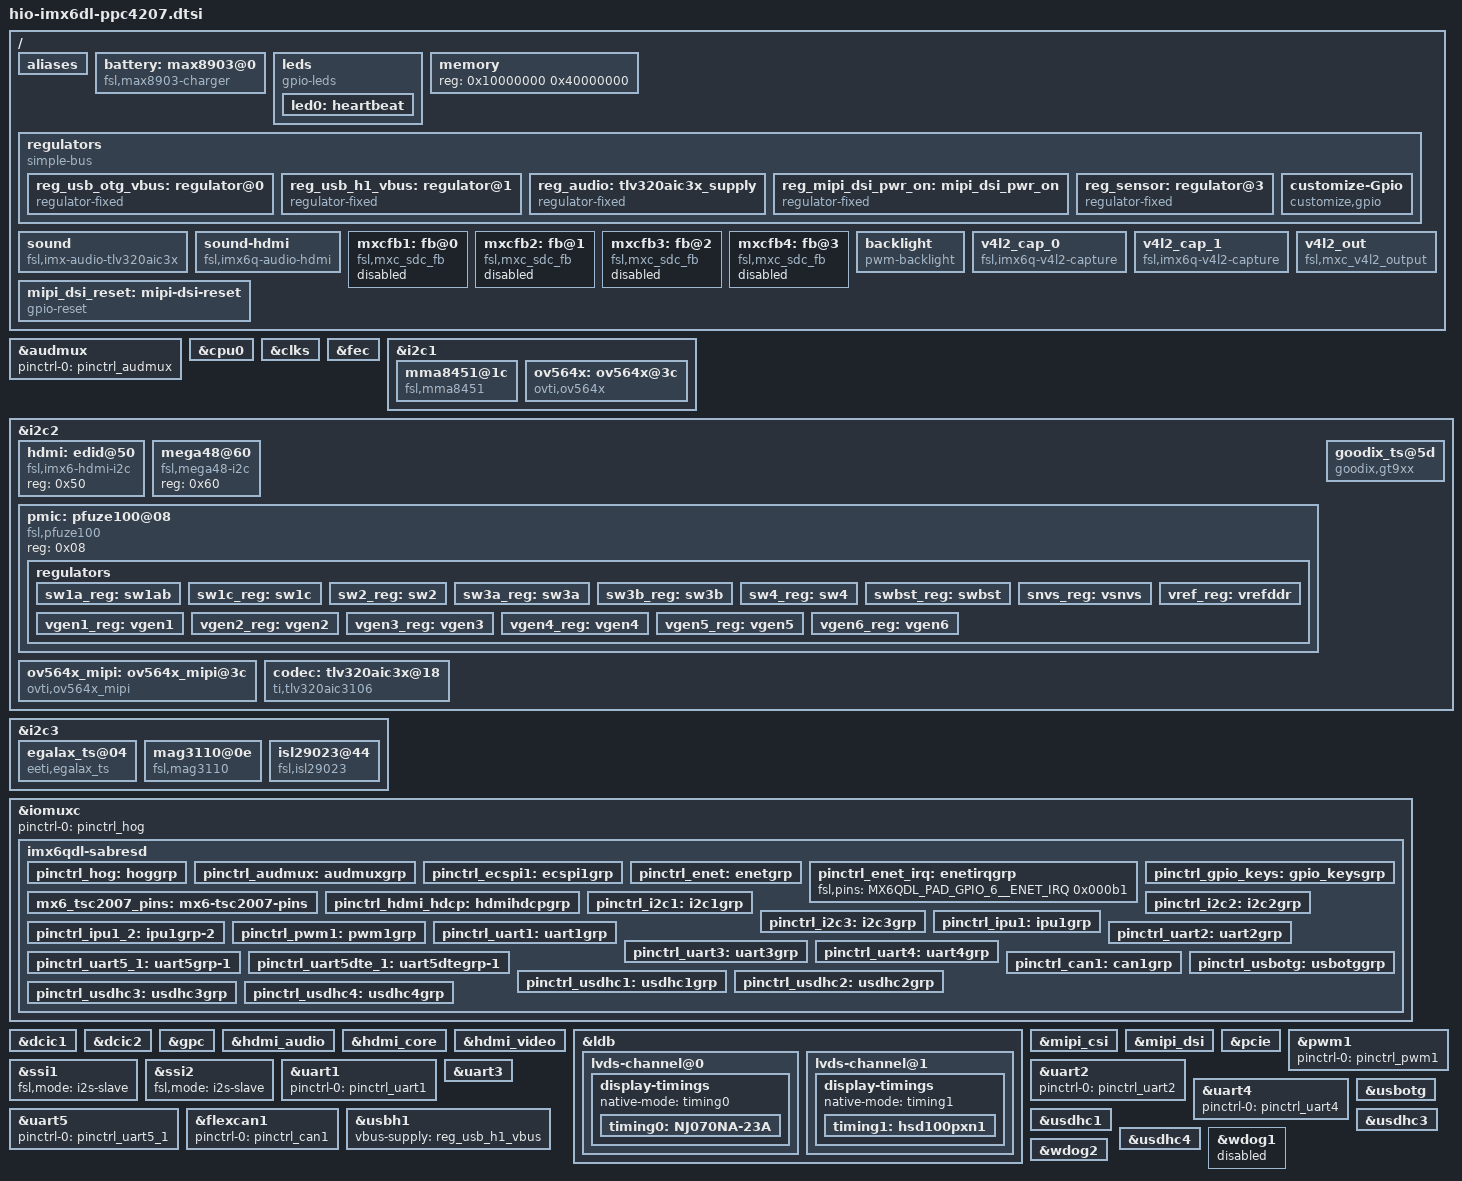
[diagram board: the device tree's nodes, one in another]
/*
 * Copyright 2012 Freescale Semiconductor, Inc.
 * Copyright 2011 Linaro Ltd.
 *
 * The code contained herein is licensed under the GNU General Public
 * License. You may obtain a copy of the GNU General Public License
 * Version 2 or later at the following locations:
 *
 * http://www.opensource.org/licenses/gpl-license.html
 * http://www.gnu.org/copyleft/gpl.html
 */

#include <dt-bindings/input/input.h>

/ {
	aliases {
		mxcfb0 = &mxcfb1;
		mxcfb1 = &mxcfb2;
		mxcfb2 = &mxcfb3;
		mxcfb3 = &mxcfb4;
	};

	battery: max8903@0 {
		compatible = "fsl,max8903-charger";
		pinctrl-names = "default";
		dok_input = <&gpio2 24 1>;
		uok_input = <&gpio1 27 1>;
		chg_input = <&gpio3 23 1>;
		flt_input = <&gpio5 2 1>;
		fsl,dcm_always_high;
		fsl,dc_valid;
		fsl,usb_valid;
		status = "okay";
	};

	#if 0
	hannstar_cabc {
		compatible = "hannstar,cabc";

		lvds0 {
			gpios = <&gpio6 15 GPIO_ACTIVE_HIGH>;
		};

		lvds1 {
			gpios = <&gpio6 16 GPIO_ACTIVE_HIGH>;
		};
	};
	#endif
	
	leds {
		compatible = "gpio-leds";

		led0: heartbeat {
             label = "heartbeat";
             gpios = <&gpio5 18 GPIO_ACTIVE_HIGH>;
             default-state = "off";
             linux,default-trigger = "heartbeat";
         };
	};

	memory: memory {
		reg = <0x10000000 0x40000000>;
	};

	regulators {
		compatible = "simple-bus";
		#address-cells = <1>;
		#size-cells = <0>;

		reg_usb_otg_vbus: regulator@0 {
			compatible = "regulator-fixed";
			reg = <0>;
			regulator-name = "usb_otg_vbus";
			regulator-min-microvolt = <5000000>;
			regulator-max-microvolt = <5000000>;
			gpio = <&gpio3 22 0>;
			enable-active-high;
			regulator-always-on;
		};

		reg_usb_h1_vbus: regulator@1 {
			compatible = "regulator-fixed";
			reg = <1>;
			regulator-name = "usb_h1_vbus";
			regulator-min-microvolt = <5000000>;
			regulator-max-microvolt = <5000000>;
			//gpio = <&gpio1 29 0>;
			enable-active-high;
			regulator-always-on;
		};

		reg_audio: tlv320aic3x_supply {
			compatible = "regulator-fixed";
			regulator-name = "tlv320aic3x-supply";
			enable-active-high;
		};
		
		#if 0
		reg_audio: regulator@2 {
			compatible = "regulator-fixed";
			reg = <2>;
			regulator-name = "wm8962-supply";
			//gpio = <&gpio4 10 0>;
			enable-active-high;
		};
		#endif
		
		reg_mipi_dsi_pwr_on: mipi_dsi_pwr_on {
			compatible = "regulator-fixed";
			regulator-name = "mipi_dsi_pwr_on";
			//gpio = <&gpio6 14 0>;
			enable-active-high;
		};

		reg_sensor: regulator@3 {
			compatible = "regulator-fixed";
			reg = <3>;
			regulator-name = "sensor-supply";
			regulator-min-microvolt = <3300000>;
			regulator-max-microvolt = <3300000>;
			gpio = <&gpio2 31 0>;
			startup-delay-us = <500>;
			enable-active-high;
		};
		
		//emb2230_gpio
		customize-Gpio {
			compatible = "customize,gpio";
			status = "okay";

			//lcd
			//LCD3P3V_Npwren = <&gpio4 11 0>;
			LCD_BL_EN = <&gpio4 17 0>;
			VDDLCD_PWREN = <&gpio4 28 0>;
			
			//tp
			TP_PWR_EN = <&gpio4 10 0>;
			
			//usb hub
			HUB_reset = <&gpio3 20 0>;
			
			//aud_mute
			AUD_MUTE = <&gpio5 00 0>;
			
			//emb2230 wl_pwren,wl_host_wake,vdd_len
			WL_PWREN = <&gpio6 15 0>;
			WL_HOST_WAKE = <&gpio6 14 0>;
			BT_PWREN = <&gpio6 10 0>;
			BT_HOST_WAKE = <&gpio6 8 0>;
			BT_RESET = <&gpio2 22 0>;
			BT_CTS = <&gpio6 05 0>;	//bt_cts--gnd	
			BT_RTS = <&gpio6 04 0>;	//bt_rts--gnd
			
			//ar8035 phy reset
			PHY_RESET = <&gpio1 29 0>;
			
			//can1_stb 
			CAN1_STB = <&gpio4 9 0>;
			
			//wifi-pwr
			WIFI_PWR = <&gpio2 0 0>;			
		};			
	};

	#if 0
	gpio-keys {
		compatible = "gpio-keys";
		pinctrl-names = "default";
		pinctrl-0 = <&pinctrl_gpio_keys>;

		power {
			label = "Power Button";
			gpios = <&gpio3 29 1>;
			gpio-key,wakeup;
			linux,code = <KEY_POWER>;
		};

		volume-up {
			label = "Volume Up";
			gpios = <&gpio1 4 1>;
			gpio-key,wakeup;
			linux,code = <KEY_VOLUMEUP>;
		};
	};
	#endif

	#if 0	
	sound {
		compatible = "fsl,imx-audio-rt5631";
		model = "imx6dl-rt5631";
		ssi-controller = <&ssi1>;
		audio-codec = <&codec>;
		audio-routing =
			"Headphone Jack", "HPOL",
			"Headphone Jack", "HPOR",
			"Ext Spk", "SPOL",
			"Ext Spk", "SPOR";
			//"MICBIAS", "AMIC",
			//"IN3R", "MICBIAS",
			//"DMIC", "MICBIAS",
			//"DMICDAT", "DMIC";
		mux-int-port = <1>;
		mux-ext-port = <4>;
		//hp-det-gpios = <&gpio7 8 1>;
		/*+++wwj begin 20150317@add mic detect*/
		#ifdef CONFIG_MIC_DEC
	              mic-det-gpios = <&gpio7 11 1>;
		#endif
		/*+++wwj end 20150317@add mic detect*/
	};
	#endif
	
	#if 0
	sound {
		compatible = "fsl,imx6q-var-som-tlv320aic3x", "fsl,imx-audio-tlv320aic3x";
		model = "tlv320aic3x-audio";
		ssi-controller = <&ssi1>;
		audio-codec = <&codec>;
		audio-routing =
			/* Headphone connected to HPLOUT, HPROUT */
			"Headphone Jack",       "HPLOUT",
			"Headphone Jack",       "HPROUT",
			/* Line Out connected to LLOUT, RLOUT */
			"Line Out",      	"LLOUT",
			"Line Out",     	"RLOUT",
			/* Mic connected to (MIC3L | MIC3R) */
			"Mic Bias",		"MIC3L",
			"Mic Bias",		"MIC3R",
			"Mic Jack",		"Mic Bias",
			/* Line In connected to (LINE1L | LINE2L), (LINE1R | LINE2R) */
			"Line In",		"LINE1L",
			"Line In",		"LINE2L",
			"Line In",		"LINE1R",
			"Line In",		"LINE2R";
		mux-int-port = <1>;
		mux-ext-port = <4>;
	};
	#endif
	
	//test ok
	sound {
		compatible = "fsl,imx-audio-tlv320aic3x";
		model = "imx6q-phyflex-tlv320aic3007";
		ssi-controller = <&ssi1>;
		audio-codec = <&codec>;
		
		#if 1
		audio-routing =
			"Line Out", "LLOUT",
			"Line Out", "RLOUT",
			"Headphone Jack", "HPLOUT",
			"Headphone Jack", "HPROUT";
		#endif

		#if 0	
                audio-routing = 
                        "Line Out", "LLOUT", 
                        "Line Out", "RLOUT", 
                        "Speaker", "SPOP", 
                        "Speaker", "SPOM", 
                        "Headphone Jack", "HPLOUT", 
                        "Headphone Jack", "HPROUT", 
                        "MIC3L", "Mic Jack", 
                        "MIC3R", "Mic Jack", 
                        "Mic Jack", "Mic Bias", 
                        "LINE1L", "Line In", 
                        "LINE1R", "Line In"; 
		#endif
		
		mux-int-port = <1>;
		mux-ext-port = <4>;
	};
	
	sound-hdmi {
		compatible = "fsl,imx6q-audio-hdmi",
			     "fsl,imx-audio-hdmi";
		model = "imx-audio-hdmi";
		hdmi-controller = <&hdmi_audio>;
	};

	mxcfb1: fb@0 {
		compatible = "fsl,mxc_sdc_fb";
		disp_dev = "ldb";
		interface_pix_fmt = "RGB24";
		mode_str ="NJ070NA-23A";
		default_bpp = <24>;
		int_clk = <0>;
		late_init = <0>;
		status = "disabled";
	};
	
	mxcfb2: fb@1 {
		compatible = "fsl,mxc_sdc_fb";
		disp_dev = "hdmi";
		interface_pix_fmt = "RGB24";
		mode_str ="1920x1080M@60";
		default_bpp = <24>;
		int_clk = <0>;
		late_init = <0>;
		status = "disabled";
	};

	mxcfb3: fb@2 {
		compatible = "fsl,mxc_sdc_fb";
		disp_dev = "lcd";
		interface_pix_fmt = "RGB565";
		mode_str ="CLAA-WVGA";
		default_bpp = <16>;
		int_clk = <0>;
		late_init = <0>;
		status = "disabled";
	};

	mxcfb4: fb@3 {
		compatible = "fsl,mxc_sdc_fb";
		disp_dev = "ldb";
		interface_pix_fmt = "RGB666";
		default_bpp = <16>;
		int_clk = <0>;
		late_init = <0>;
		status = "disabled";
	};

	#if 0
	lcd@0 {
		compatible = "fsl,lcd";
		ipu_id = <0>;
		disp_id = <0>;
		default_ifmt = "RGB565";
		pinctrl-names = "default";
		pinctrl-0 = <&pinctrl_ipu1>;
		status = "okay";
	};
	#endif
	
	backlight {
		compatible = "pwm-backlight";
		pwms = <&pwm1 0 5000000>;
		brightness-levels = <0 4 8 16 32 64 128 255>;
		default-brightness-level = <7>;
		status = "okay";
	};

	v4l2_cap_0 {
		compatible = "fsl,imx6q-v4l2-capture";
		ipu_id = <0>;
		csi_id = <0>;
		mclk_source = <0>;
		status = "okay";
	};

	v4l2_cap_1 {
		compatible = "fsl,imx6q-v4l2-capture";
		ipu_id = <0>;
		csi_id = <1>;
		mclk_source = <0>;
		status = "okay";
	};

	v4l2_out {
		compatible = "fsl,mxc_v4l2_output";
		status = "okay";
	};

	mipi_dsi_reset: mipi-dsi-reset {
		compatible = "gpio-reset";
		reset-gpios = <&gpio6 11 GPIO_ACTIVE_LOW>;
		reset-delay-us = <50>;
		#reset-cells = <0>;
	};
};

&audmux {
	pinctrl-names = "default";
	pinctrl-0 = <&pinctrl_audmux>;
	status = "okay";
};

&cpu0 {
	arm-supply = <&sw1a_reg>;
	soc-supply = <&sw1c_reg>;
};

&clks {
	fsl,ldb-di0-parent = <&clks IMX6QDL_CLK_PLL2_PFD0_352M>;
	fsl,ldb-di1-parent = <&clks IMX6QDL_CLK_PLL2_PFD0_352M>;
};

#if 0
&ecspi1 {
	fsl,spi-num-chipselects = <1>;
	cs-gpios = <&gpio4 9 0>;
	pinctrl-names = "default";
	pinctrl-0 = <&pinctrl_ecspi1>;
	status = "okay";

	flash: m25p80@0 {
		#address-cells = <1>;
		#size-cells = <1>;
		compatible = "st,m25p32";
		spi-max-frequency = <20000000>;
		reg = <0>;
	};
};
#endif

&fec {
	pinctrl-names = "default";
	pinctrl-0 = <&pinctrl_enet>;
	phy-mode = "rgmii";
	phy-reset-gpios = <&gpio1 25 0>;
	fsl,magic-packet;
	status = "okay";
};

&i2c1 {
	clock-frequency = <100000>;
	pinctrl-names = "default";
	pinctrl-0 = <&pinctrl_i2c1>;
	status = "okay";

	mma8451@1c {
		compatible = "fsl,mma8451";
		reg = <0x1c>;
		position = <0>;
		vdd-supply = <&reg_sensor>;
		vddio-supply = <&reg_sensor>;
		interrupt-parent = <&gpio1>;
		interrupts = <18 8>;
		interrupt-route = <1>;
	};
		
	ov564x: ov564x@3c {
		compatible = "ovti,ov564x";
		reg = <0x3c>;
		pinctrl-names = "default";
		pinctrl-0 = <&pinctrl_ipu1_2>;
		clocks = <&clks IMX6QDL_CLK_CKO>;
		clock-names = "csi_mclk";
		DOVDD-supply = <&vgen4_reg>; /* 1.8v */
		AVDD-supply = <&vgen3_reg>;  /* 2.8v, on rev C board is VGEN3,
						on rev B board is VGEN5 */
		DVDD-supply = <&vgen2_reg>;  /* 1.5v*/
		pwn-gpios = <&gpio1 16 1>;   /* active low: SD1_DAT0 */
		rst-gpios = <&gpio1 17 0>;   /* active high: SD1_DAT1 */
		csi_id = <0>;
		mclk = <24000000>;
		mclk_source = <0>;
	};
};

&i2c2 {
	//clock-frequency = <100000>;
	clock-frequency = <50000>;
	pinctrl-names = "default";
	pinctrl-0 = <&pinctrl_i2c2>;
	status = "okay";

	hdmi: edid@50 {
		compatible = "fsl,imx6-hdmi-i2c";
		reg = <0x50>;
	};

	mega48@60 {
		compatible = "fsl,mega48-i2c";
		reg = <0x60>;
	};
	
	pmic: pfuze100@08 {
		compatible = "fsl,pfuze100";
		reg = <0x08>;

		regulators {
			sw1a_reg: sw1ab {
				regulator-min-microvolt = <300000>;
				regulator-max-microvolt = <1875000>;
				regulator-boot-on;
				regulator-always-on;
				regulator-ramp-delay = <6250>;
			};

			sw1c_reg: sw1c {
				regulator-min-microvolt = <300000>;
				regulator-max-microvolt = <1875000>;
				regulator-boot-on;
				regulator-always-on;
				regulator-ramp-delay = <6250>;
			};

			sw2_reg: sw2 {
				regulator-min-microvolt = <800000>;
				regulator-max-microvolt = <3300000>;
				regulator-boot-on;
				regulator-always-on;
				regulator-ramp-delay = <6250>;
			};

			sw3a_reg: sw3a {
				regulator-min-microvolt = <400000>;
				regulator-max-microvolt = <1975000>;
				regulator-boot-on;
				regulator-always-on;
			};

			sw3b_reg: sw3b {
				regulator-min-microvolt = <400000>;
				regulator-max-microvolt = <1975000>;
				regulator-boot-on;
				regulator-always-on;
			};

			sw4_reg: sw4 {
				regulator-min-microvolt = <800000>;
				regulator-max-microvolt = <3300000>;
			};

			swbst_reg: swbst {
				regulator-min-microvolt = <5000000>;
				regulator-max-microvolt = <5150000>;
			};

			snvs_reg: vsnvs {
				regulator-min-microvolt = <1000000>;
				regulator-max-microvolt = <3000000>;
				regulator-boot-on;
				regulator-always-on;
			};

			vref_reg: vrefddr {
				regulator-boot-on;
				regulator-always-on;
			};

			vgen1_reg: vgen1 {
				regulator-min-microvolt = <800000>;
				regulator-max-microvolt = <1550000>;
			};

			vgen2_reg: vgen2 {
				regulator-min-microvolt = <800000>;
				regulator-max-microvolt = <1550000>;
			};

			vgen3_reg: vgen3 {
				regulator-min-microvolt = <1800000>;
				regulator-max-microvolt = <3300000>;
			};

			vgen4_reg: vgen4 {
				regulator-min-microvolt = <1800000>;
				regulator-max-microvolt = <3300000>;
				regulator-always-on;
			};

			vgen5_reg: vgen5 {
				regulator-min-microvolt = <1800000>;
				regulator-max-microvolt = <3300000>;
				regulator-always-on;
			};

			vgen6_reg: vgen6 {
				regulator-min-microvolt = <1800000>;
				regulator-max-microvolt = <3300000>;
				regulator-always-on;
			};
		};
	};

	ov564x_mipi: ov564x_mipi@3c { /* i2c2 driver */
		compatible = "ovti,ov564x_mipi";
		reg = <0x3c>;
		clocks = <&clks 201>;
		clock-names = "csi_mclk";
		DOVDD-supply = <&vgen4_reg>; /* 1.8v */
		AVDD-supply = <&vgen3_reg>;  /* 2.8v, rev C board is VGEN3
						rev B board is VGEN5 */
		DVDD-supply = <&vgen2_reg>;  /* 1.5v*/
		pwn-gpios = <&gpio1 19 1>;   /* active low: SD1_CLK */
		rst-gpios = <&gpio1 20 0>;   /* active high: SD1_DAT2 */
		csi_id = <1>;
		mclk = <24000000>;
		mclk_source = <0>;
	};

	#if 0
	egalax_ts@04 {
		compatible = "eeti,egalax_ts";
		reg = <0x04>;
		interrupt-parent = <&gpio6>;
		interrupts = <8 2>;
		wakeup-gpios = <&gpio6 8 0>;
	};
	#endif
	
	#if 0
	codec: rt5631@1a {
		  compatible = "realtek,rt5631";
		  //compatible = "realtek,alc5631";
		  reg = <0x1a>;
		  clocks = <&clks 201>;
	};
	#endif
	
	
	codec: tlv320aic3x@18 {
		//compatible = "ti,tlv320aic3x";
		compatible = "ti,tlv320aic3106";
		reg = <0x18>;
		ai3x-micbias-vg = <2>;
		
		clocks = <&clks 201>;
		clock-names = "clko_clk";
		IOVDD-supply = <&reg_audio>;
		DVDD-supply = <&reg_audio>;
		AVDD-supply = <&reg_audio>;
		DRVDD-supply = <&reg_audio>;
		gpio-reset = <&gpio5 13 1>;
		gpio-cfg = <
			0x0000 /* 0:Default */
			0x0000 /* 1:Default */
			0x0013 /* 2:FN_DMICCLK */
			0x0000 /* 3:Default */
			0x8014 /* 4:FN_DMICCDAT */
			0x0000 /* 5:Default */
		>;
	};	
	
	//emb2230 tp
	goodix_ts@5d {
		compatible = "goodix,gt9xx";
		reg = <0x5d>;
		interrupt-parent = <&gpio4>;
		interrupts = <27 3>;
		//vdd_ana-supply = <&pm8226_l19>;
		//vcc_i2c-supply = <&pm8226_lvs1>;
		goodix,rst-gpio = <&gpio4 26 0>;
		goodix,irq-gpio = <&gpio4 27 0>;
		goodix,cfg-group0 = [
			42 D0 02 00 05 05 75 01 01 0F 24 
			0F 64 3C 03 05 00 00 00 02 00 00 
			00 16 19 1C 14 8C 0E 0E 24 00 31 
			0D 00 00 00 83 33 1D 00 41 00 00 
			00 00 00 08 0A 00 2B 1C 3C 94 D5 
			03 08 00 00 04 93 1E 00 82 23 00 
			74 29 00 69 2F 00 5F 37 00 5F 20 
			40 60 00 F0 40 30 55 50 27 00 00 
			00 00 00 00 00 00 00 00 00 00 00 
			00 00 00 00 00 00 00 14 19 00 00 
			50 50 02 04 06 08 0A 0C 0E 10 12 
			14 16 18 1A 1C 00 00 00 00 00 00 
			00 00 00 00 00 00 00 00 00 00 1D 
			1E 1F 20 21 22 24 26 28 29 2A 1C 
			18 16 14 13 12 10 0F 0C 0A 08 06 
			04 02 00 00 00 00 00 00 00 00 00 
			00 00 00 00 00 00 00 00 9C 01];
		
		goodix,cfg-group2 = [
			48 D0 02 00 05 05 75 01 01 0F 24 
			0F 64 3C 03 05 00 00 00 02 00 00 
			00 16 19 1C 14 8C 0E 0E 24 00 31 
			0D 00 00 00 83 33 1D 00 41 00 00 
			3C 0A 14 08 0A 00 2B 1C 3C 94 D5 
			03 08 00 00 04 93 1E 00 82 23 00 
			74 29 00 69 2F 00 5F 37 00 5F 20 
			40 60 00 F0 40 30 55 50 27 00 00 
			00 00 00 00 00 00 00 00 00 00 00 
			00 00 00 00 00 00 00 14 19 00 00 
			50 50 02 04 06 08 0A 0C 0E 10 12 
			14 16 18 1A 1C 00 00 00 00 00 00 
			00 00 00 00 00 00 00 00 00 00 1D 
			1E 1F 20 21 22 24 26 28 29 2A 1C 
			18 16 14 13 12 10 0F 0C 0A 08 06 
			04 02 00 00 00 00 00 00 00 00 00 
			00 00 00 00 00 00 00 00 3C 01];
	};			
};

&i2c3 {
	clock-frequency = <100000>;
	pinctrl-names = "default";
	pinctrl-0 = <&pinctrl_i2c3>;
	status = "okay";

	egalax_ts@04 {
		compatible = "eeti,egalax_ts";
		reg = <0x04>;
		interrupt-parent = <&gpio6>;
		interrupts = <7 2>;
		wakeup-gpios = <&gpio6 7 0>;
	};

	mag3110@0e {
		compatible = "fsl,mag3110";
		reg = <0x0e>;
		position = <2>;
		vdd-supply = <&reg_sensor>;
		vddio-supply = <&reg_sensor>;
		interrupt-parent = <&gpio3>;
		interrupts = <16 1>;
	};

	isl29023@44 {
		compatible = "fsl,isl29023";
		reg = <0x44>;
		rext = <499>;
		vdd-supply = <&reg_sensor>;
		interrupt-parent = <&gpio3>;
		interrupts = <9 2>;
	};
};

&iomuxc {
	pinctrl-names = "default";
	pinctrl-0 = <&pinctrl_hog>;

	imx6qdl-sabresd {
		pinctrl_hog: hoggrp {
			fsl,pins = <
				//MX6QDL_PAD_NANDF_D0__GPIO2_IO00 0x80000000
				MX6QDL_PAD_NANDF_D1__GPIO2_IO01 0x80000000
				MX6QDL_PAD_NANDF_D2__GPIO2_IO02 0x80000000
				MX6QDL_PAD_NANDF_D3__GPIO2_IO03 0x80000000
				MX6QDL_PAD_GPIO_0__CCM_CLKO1    0x130b0
				MX6QDL_PAD_NANDF_CLE__GPIO6_IO07 0x80000000
				//MX6QDL_PAD_NANDF_ALE__GPIO6_IO08 0x80000000
				MX6QDL_PAD_EIM_D22__GPIO3_IO22  0x80000000
				MX6QDL_PAD_ENET_CRS_DV__GPIO1_IO25 0x80000000
				MX6QDL_PAD_EIM_CS1__GPIO2_IO24 0x80000000
				MX6QDL_PAD_ENET_RXD0__GPIO1_IO27 0x80000000
				MX6QDL_PAD_EIM_A25__GPIO5_IO02 0x80000000
				//MX6QDL_PAD_EIM_D23__GPIO3_IO23 0x80000000
				MX6QDL_PAD_EIM_EB3__GPIO2_IO31 0x80000000
				//MX6QDL_PAD_SD1_CMD__GPIO1_IO18 0x80000000
				MX6QDL_PAD_EIM_D16__GPIO3_IO16 0x80000000
				MX6QDL_PAD_SD3_RST__GPIO7_IO08	0x80000000
				MX6QDL_PAD_EIM_DA9__GPIO3_IO09 0x80000000
				//MX6QDL_PAD_GPIO_1__WDOG2_B 0x80000000
				MX6QDL_PAD_NANDF_CS0__GPIO6_IO11 0x80000000
				//MX6QDL_PAD_NANDF_CS1__GPIO6_IO14 0x80000000
				//MX6QDL_PAD_NANDF_CS2__GPIO6_IO15 0x80000000
				MX6QDL_PAD_NANDF_CS3__GPIO6_IO16 0x80000000
				
				//lcd
				MX6QDL_PAD_DI0_PIN15__GPIO4_IO17	0x80000000
				MX6QDL_PAD_DISP0_DAT7__GPIO4_IO28	0x80000000	
				
				//tp int;rst
				MX6QDL_PAD_DISP0_DAT6__GPIO4_IO27	0x80000000
				MX6QDL_PAD_DISP0_DAT5__GPIO4_IO26	0x80000000
				
				//rtl8111e
				MX6QDL_PAD_KEY_COL4__GPIO4_IO14	0x80000000
				
				//usb_hub
				MX6QDL_PAD_KEY_COL0__GPIO4_IO06 0x80000000
							
				//emb2230 sd4_cd
				MX6QDL_PAD_GPIO_4__GPIO1_IO04	0x80000000
				
				//emb2230 usb-hub
				MX6QDL_PAD_EIM_D20__GPIO3_IO20 	0x80000000
				
				//rst_aud aud_mute
				MX6QDL_PAD_DISP0_DAT19__GPIO5_IO13	0x80000000
				MX6QDL_PAD_EIM_WAIT__GPIO5_IO00	0x80000000
				
				//two gpio
				MX6QDL_PAD_DI0_PIN4__GPIO4_IO20	0x80000000
				MX6QDL_PAD_DI0_PIN2__GPIO4_IO18	0x80000000
				
				//emb2230 wifi
				MX6QDL_PAD_NANDF_CS1__GPIO6_IO14	0x80000000
				MX6QDL_PAD_NANDF_CS2__GPIO6_IO15	0x80000000
				
				//emb2230 bt
				MX6QDL_PAD_NANDF_RB0__GPIO6_IO10        0x80000000 //bt_en
				MX6QDL_PAD_NANDF_ALE__GPIO6_IO08        0x80000000 //bt_irq
				MX6QDL_PAD_EIM_A16__GPIO2_IO22          0x80000000 //bt_rst		
				MX6QDL_PAD_CSI0_DAT18__GPIO6_IO04		0x80000000 //bt_rts--gnd
				MX6QDL_PAD_CSI0_DAT19__GPIO6_IO05		0x80000000 //bt_cts--gnd	
				
				//ar8035 phy reset
				MX6QDL_PAD_ENET_TXD1__GPIO1_IO29 		0x80000000
				
				//can1_stb 
				MX6QDL_PAD_KEY_ROW1__GPIO4_IO09 		0x80000000	

				//run-led
				MX6QDL_PAD_CSI0_PIXCLK__GPIO5_IO18		0x80000000
				
				//wifi-gpio
				MX6QDL_PAD_NANDF_D0__GPIO2_IO00                 0x80000000				
			>;
		};

		pinctrl_audmux: audmuxgrp {
			fsl,pins = <
				MX6QDL_PAD_DISP0_DAT23__AUD4_RXD  0x130b0
				MX6QDL_PAD_DISP0_DAT20__AUD4_TXC  0x130b0
				MX6QDL_PAD_DISP0_DAT21__AUD4_TXD  0x110b0
				MX6QDL_PAD_DISP0_DAT22__AUD4_TXFS 0x130b0
			
				//MX6QDL_PAD_GPIO_0__CCM_CLKO1  0x1f0b0 //MQ +++
				//MX6QDL_PAD_GPIO_0__CCM_CLKO1  0x130b0 //ben +++
			>;
		};

		pinctrl_ecspi1: ecspi1grp {
			fsl,pins = <
				MX6QDL_PAD_KEY_COL1__ECSPI1_MISO	0x100b1
				MX6QDL_PAD_KEY_ROW0__ECSPI1_MOSI	0x100b1
				//MX6QDL_PAD_KEY_COL0__ECSPI1_SCLK	0x100b1
			>;
		};

		pinctrl_enet: enetgrp {
			fsl,pins = <
				MX6QDL_PAD_ENET_MDIO__ENET_MDIO		0x1b0b0
				MX6QDL_PAD_ENET_MDC__ENET_MDC		0x1b0b0
				MX6QDL_PAD_RGMII_TXC__RGMII_TXC		0x1b0b0
				MX6QDL_PAD_RGMII_TD0__RGMII_TD0		0x1b0b0
				MX6QDL_PAD_RGMII_TD1__RGMII_TD1		0x1b0b0
				MX6QDL_PAD_RGMII_TD2__RGMII_TD2		0x1b0b0
				MX6QDL_PAD_RGMII_TD3__RGMII_TD3		0x1b0b0
				MX6QDL_PAD_RGMII_TX_CTL__RGMII_TX_CTL	0x1b0b0
				MX6QDL_PAD_ENET_REF_CLK__ENET_TX_CLK	0x1b0b0
				MX6QDL_PAD_RGMII_RXC__RGMII_RXC		0x1b0b0
				MX6QDL_PAD_RGMII_RD0__RGMII_RD0		0x1b0b0
				MX6QDL_PAD_RGMII_RD1__RGMII_RD1		0x1b0b0
				MX6QDL_PAD_RGMII_RD2__RGMII_RD2		0x1b0b0
				MX6QDL_PAD_RGMII_RD3__RGMII_RD3		0x1b0b0
				MX6QDL_PAD_RGMII_RX_CTL__RGMII_RX_CTL	0x1b0b0
				MX6QDL_PAD_GPIO_16__ENET_REF_CLK	0x4001b0a8
			>;
		};

		pinctrl_enet_irq: enetirqgrp {
			fsl,pins = <
				MX6QDL_PAD_GPIO_6__ENET_IRQ		0x000b1
			>;
		};

		pinctrl_gpio_keys: gpio_keysgrp {
			fsl,pins = <
				MX6QDL_PAD_EIM_D29__GPIO3_IO29 0x80000000
				//MX6QDL_PAD_GPIO_4__GPIO1_IO04  0x80000000
			>;
		};

		mx6_tsc2007_pins: mx6-tsc2007-pins {
            fsl,pins = <
                MX6QDL_PAD_GPIO_1__GPIO1_IO01 0x80000000 //test /* TSC2007 IRQ */
				//MX6QDL_PAD_GPIO_5__GPIO1_IO05 0x80000000
             >; /*
            fsl,drive-strength = <MXS_DRIVE_4mA>;
            fsl,voltage = <MXS_VOLTAGE_HIGH>;
            fsl,pull-up = <MXS_PULL_DISABLE>; */
       }; 
		
		//pinctrl_hdmi_cec: hdmicecgrp {
		//	fsl,pins = <
		//		MX6QDL_PAD_KEY_ROW2__HDMI_TX_CEC_LINE 0x1f8b0
		//	>;
		//};

		pinctrl_hdmi_hdcp: hdmihdcpgrp {
			fsl,pins = <
				MX6QDL_PAD_KEY_COL3__HDMI_TX_DDC_SCL 0x4001b8b1
				MX6QDL_PAD_KEY_ROW3__HDMI_TX_DDC_SDA 0x4001b8b1
			>;
		};

		pinctrl_i2c1: i2c1grp {
			fsl,pins = <
				MX6QDL_PAD_CSI0_DAT8__I2C1_SDA		0x4001b8b1
				MX6QDL_PAD_CSI0_DAT9__I2C1_SCL		0x4001b8b1
			>;
		};

		pinctrl_i2c2: i2c2grp {
			fsl,pins = <
				MX6QDL_PAD_KEY_COL3__I2C2_SCL		0x4001b8b1
				MX6QDL_PAD_KEY_ROW3__I2C2_SDA		0x4001b8b1				
			 >;
		};

		pinctrl_i2c3: i2c3grp {
			fsl,pins = <
				MX6QDL_PAD_EIM_D17__I2C3_SCL		0x4001b8b1
				MX6QDL_PAD_EIM_D18__I2C3_SDA		0x4001b8b1
			>;
		};

		pinctrl_ipu1: ipu1grp {
			fsl,pins = <
				MX6QDL_PAD_DI0_DISP_CLK__IPU1_DI0_DISP_CLK 0x10
				//MX6QDL_PAD_DI0_PIN15__IPU1_DI0_PIN15       0x10
				//MX6QDL_PAD_DI0_PIN2__IPU1_DI0_PIN02        0x10
				MX6QDL_PAD_DI0_PIN3__IPU1_DI0_PIN03        0x10
				//MX6QDL_PAD_DI0_PIN4__IPU1_DI0_PIN04        0x80000000
				MX6QDL_PAD_DISP0_DAT0__IPU1_DISP0_DATA00   0x10
				MX6QDL_PAD_DISP0_DAT1__IPU1_DISP0_DATA01   0x10
				MX6QDL_PAD_DISP0_DAT2__IPU1_DISP0_DATA02   0x10
				MX6QDL_PAD_DISP0_DAT3__IPU1_DISP0_DATA03   0x10
				MX6QDL_PAD_DISP0_DAT4__IPU1_DISP0_DATA04   0x10
				//MX6QDL_PAD_DISP0_DAT5__IPU1_DISP0_DATA05   0x10
				//MX6QDL_PAD_DISP0_DAT6__IPU1_DISP0_DATA06   0x10
				//MX6QDL_PAD_DISP0_DAT7__IPU1_DISP0_DATA07   0x10
				//MX6QDL_PAD_DISP0_DAT8__IPU1_DISP0_DATA08   0x10
				MX6QDL_PAD_DISP0_DAT9__IPU1_DISP0_DATA09   0x10
				MX6QDL_PAD_DISP0_DAT10__IPU1_DISP0_DATA10  0x10
				MX6QDL_PAD_DISP0_DAT11__IPU1_DISP0_DATA11  0x10
				MX6QDL_PAD_DISP0_DAT12__IPU1_DISP0_DATA12  0x10
				MX6QDL_PAD_DISP0_DAT13__IPU1_DISP0_DATA13  0x10
				MX6QDL_PAD_DISP0_DAT14__IPU1_DISP0_DATA14  0x10
				MX6QDL_PAD_DISP0_DAT15__IPU1_DISP0_DATA15  0x10
				MX6QDL_PAD_DISP0_DAT16__IPU1_DISP0_DATA16  0x10
				MX6QDL_PAD_DISP0_DAT17__IPU1_DISP0_DATA17  0x10
				MX6QDL_PAD_DISP0_DAT18__IPU1_DISP0_DATA18  0x10
				//MX6QDL_PAD_DISP0_DAT19__IPU1_DISP0_DATA19  0x10
				//MX6QDL_PAD_DISP0_DAT20__IPU1_DISP0_DATA20  0x10
				//MX6QDL_PAD_DISP0_DAT21__IPU1_DISP0_DATA21  0x10
				//MX6QDL_PAD_DISP0_DAT22__IPU1_DISP0_DATA22  0x10
				//MX6QDL_PAD_DISP0_DAT23__IPU1_DISP0_DATA23  0x10
			>;
		};

		pinctrl_ipu1_2: ipu1grp-2 { /* parallel camera */
			fsl,pins = <
				//MX6QDL_PAD_CSI0_DAT12__IPU1_CSI0_DATA12    0x80000000
				//MX6QDL_PAD_CSI0_DAT13__IPU1_CSI0_DATA13    0x80000000
				//MX6QDL_PAD_CSI0_DAT14__IPU1_CSI0_DATA14    0x80000000
				//MX6QDL_PAD_CSI0_DAT15__IPU1_CSI0_DATA15    0x80000000
				MX6QDL_PAD_CSI0_DAT16__IPU1_CSI0_DATA16    0x80000000
				MX6QDL_PAD_CSI0_DAT17__IPU1_CSI0_DATA17    0x80000000
				//MX6QDL_PAD_CSI0_DAT18__IPU1_CSI0_DATA18    0x80000000
				//MX6QDL_PAD_CSI0_DAT19__IPU1_CSI0_DATA19    0x80000000
				MX6QDL_PAD_CSI0_DATA_EN__IPU1_CSI0_DATA_EN 0x80000000
				//MX6QDL_PAD_CSI0_PIXCLK__IPU1_CSI0_PIXCLK   0x80000000
				MX6QDL_PAD_CSI0_MCLK__IPU1_CSI0_HSYNC      0x80000000
				MX6QDL_PAD_CSI0_VSYNC__IPU1_CSI0_VSYNC     0x80000000
			>;
		};

		pinctrl_pwm1: pwm1grp {
			fsl,pins = <
				MX6QDL_PAD_DISP0_DAT8__PWM1_OUT	0x1b0b1
			>;
		};

		pinctrl_uart1: uart1grp {
			fsl,pins = <
				MX6QDL_PAD_CSI0_DAT10__UART1_TX_DATA	0x1b0b1
				MX6QDL_PAD_CSI0_DAT11__UART1_RX_DATA	0x1b0b1
			>;
		};

		pinctrl_uart2: uart2grp {
			fsl,pins = <
				MX6QDL_PAD_EIM_D27__UART2_RX_DATA 0x1b0b1
                MX6QDL_PAD_EIM_D26__UART2_TX_DATA 0x1b0b1
			>;
		};
		
		pinctrl_uart3: uart3grp {
			fsl,pins = <
				MX6QDL_PAD_EIM_D25__UART3_RX_DATA 0x1b0b1
                MX6QDL_PAD_EIM_D24__UART3_TX_DATA 0x1b0b1
				MX6QDL_PAD_EIM_D23__UART3_CTS_B	  0x1b0b1
			>;
		};

		pinctrl_uart4: uart4grp {
			fsl,pins = <
				MX6QDL_PAD_CSI0_DAT12__UART4_TX_DATA 0x1b0b1
                MX6QDL_PAD_CSI0_DAT13__UART4_RX_DATA 0x1b0b1
			>;
		};
		
		pinctrl_uart5_1: uart5grp-1 {
			fsl,pins = <
				MX6QDL_PAD_CSI0_DAT14__UART5_TX_DATA    0x1b0b1
				MX6QDL_PAD_CSI0_DAT15__UART5_RX_DATA    0x1b0b1
				//MX6QDL_PAD_CSI0_DAT18__UART5_RTS_B      0x1b0b1
				//MX6QDL_PAD_CSI0_DAT19__UART5_CTS_B      0x1b0b1
			>;
		};

		pinctrl_uart5dte_1: uart5dtegrp-1 {
			fsl,pins = <
				//MX6QDL_PAD_KEY_ROW1__UART5_TX_DATA	0x1b0b1
				MX6QDL_PAD_KEY_COL1__UART5_RX_DATA	0x1b0b1
				MX6QDL_PAD_KEY_ROW4__UART5_RTS_B	0x1b0b1
				//MX6QDL_PAD_KEY_COL4__UART5_CTS_B	0x1b0b1
			>;
		};

		pinctrl_can1: can1grp {
			fsl,pins = <
				MX6QDL_PAD_KEY_COL2__FLEXCAN1_TX	0x1b0b0
				MX6QDL_PAD_KEY_ROW2__FLEXCAN1_RX	0x1b0b0
			>;
		};

		pinctrl_usbotg: usbotggrp {
			fsl,pins = <
				MX6QDL_PAD_ENET_RX_ER__USB_OTG_ID	0x17059
			>;
		};

		pinctrl_usdhc1: usdhc1grp {
			fsl,pins = <
				MX6QDL_PAD_SD1_CMD__SD1_CMD             0x17059
                MX6QDL_PAD_SD1_CLK__SD1_CLK             0x10059
                MX6QDL_PAD_SD1_DAT0__SD1_DATA0          0x17059
				MX6QDL_PAD_SD1_DAT1__SD1_DATA1          0x17059
				MX6QDL_PAD_SD1_DAT2__SD1_DATA2          0x17059
				MX6QDL_PAD_SD1_DAT3__SD1_DATA3          0x17059
			>;
		};
		
		pinctrl_usdhc2: usdhc2grp {
			fsl,pins = <
				MX6QDL_PAD_SD2_CMD__SD2_CMD		0x17059
				MX6QDL_PAD_SD2_CLK__SD2_CLK		0x10059
				MX6QDL_PAD_SD2_DAT0__SD2_DATA0		0x17059
				MX6QDL_PAD_SD2_DAT1__SD2_DATA1		0x17059
				MX6QDL_PAD_SD2_DAT2__SD2_DATA2		0x17059
				MX6QDL_PAD_SD2_DAT3__SD2_DATA3		0x17059
				MX6QDL_PAD_NANDF_D4__SD2_DATA4		0x17059
				MX6QDL_PAD_NANDF_D5__SD2_DATA5		0x17059
				MX6QDL_PAD_NANDF_D6__SD2_DATA6		0x17059
				MX6QDL_PAD_NANDF_D7__SD2_DATA7		0x17059
			>;
		};

		pinctrl_usdhc3: usdhc3grp {
			fsl,pins = <
				MX6QDL_PAD_SD3_CMD__SD3_CMD		0x17059
				MX6QDL_PAD_SD3_CLK__SD3_CLK		0x10059
				MX6QDL_PAD_SD3_DAT0__SD3_DATA0		0x17059
				MX6QDL_PAD_SD3_DAT1__SD3_DATA1		0x17059
				MX6QDL_PAD_SD3_DAT2__SD3_DATA2		0x17059
				MX6QDL_PAD_SD3_DAT3__SD3_DATA3		0x17059
				MX6QDL_PAD_SD3_DAT4__SD3_DATA4		0x17059
				MX6QDL_PAD_SD3_DAT5__SD3_DATA5		0x17059
				MX6QDL_PAD_SD3_DAT6__SD3_DATA6		0x17059
				MX6QDL_PAD_SD3_DAT7__SD3_DATA7		0x17059
			>;
		};

		pinctrl_usdhc4: usdhc4grp {
			fsl,pins = <
				MX6QDL_PAD_SD4_CMD__SD4_CMD		0x17059
				MX6QDL_PAD_SD4_CLK__SD4_CLK		0x10059
				MX6QDL_PAD_SD4_DAT0__SD4_DATA0		0x17059
				MX6QDL_PAD_SD4_DAT1__SD4_DATA1		0x17059
				MX6QDL_PAD_SD4_DAT2__SD4_DATA2		0x17059
				MX6QDL_PAD_SD4_DAT3__SD4_DATA3		0x17059
				//MX6QDL_PAD_SD4_DAT4__SD4_DATA4		0x17059
				//MX6QDL_PAD_SD4_DAT5__SD4_DATA5		0x17059
				//MX6QDL_PAD_SD4_DAT6__SD4_DATA6		0x17059
				//MX6QDL_PAD_SD4_DAT7__SD4_DATA7		0x17059
			>;
		};

	};
};

&dcic1 {
	dcic_id = <0>;
	dcic_mux = "dcic-hdmi";
	status = "okay";
};

&dcic2 {
	dcic_id = <1>;
	dcic_mux = "dcic-lvds1";
	status = "okay";
};

&gpc {
	/* use ldo-bypass, u-boot will check it and configure */
	fsl,ldo-bypass = <1>;
	fsl,wdog-reset = <1>;
};

&hdmi_audio {
	status = "okay";
};

//&hdmi_cec {
//	pinctrl-names = "default";
//	pinctrl-0 = <&pinctrl_hdmi_cec>;
//	status = "okay";
//};

&hdmi_core {
	ipu_id = <0>;
	disp_id = <0>;
	status = "okay";
};

&hdmi_video {
	fsl,phy_reg_vlev = <0x0294>;
	fsl,phy_reg_cksymtx = <0x800d>;
	status = "okay";
};

&ldb {
	status = "okay";

	lvds-channel@0 {
		fsl,data-mapping = "spwg";
		fsl,data-width = <24>;
		primary;
		status = "okay";
	
		display-timings {
			native-mode = <&timing0>;
			timing0: NJ070NA-23A {
				clock-frequency = <51200000>;
				hactive = <1024>;
				vactive = <600>;
				hback-porch = <200>;
				hfront-porch = <120>;
				vback-porch = <20>;
				vfront-porch = <15>;
				hsync-len = <5>;
				vsync-len = <5>;
			};
		};
	};	

	lvds-channel@1 {
		fsl,data-mapping = "spwg";
		fsl,data-width = <18>;
		//primary;
		status = "okay";

		display-timings {
			native-mode = <&timing1>;
			timing1: hsd100pxn1 {
				clock-frequency = <65000000>;
				hactive = <1024>;
				vactive = <768>;
				hback-porch = <220>;
				hfront-porch = <40>;
				vback-porch = <21>;
				vfront-porch = <7>;
				hsync-len = <60>;
				vsync-len = <10>;
			};
		};
	};
};

&mipi_csi {
	status = "okay";
	ipu_id = <0>;
	csi_id = <1>;
	v_channel = <0>;
	lanes = <2>;
};

&mipi_dsi {
	dev_id = <0>;
	disp_id = <1>;
	lcd_panel = "TRULY-WVGA";
	disp-power-on-supply = <&reg_mipi_dsi_pwr_on>;
	resets = <&mipi_dsi_reset>;
	status = "okay";
};

&pcie {
	power-on-gpio = <&gpio3 19 0>;
	reset-gpio = <&gpio4 14 0>;
	
	status = "okay";
};

&pwm1 {
	pinctrl-names = "default";
	pinctrl-0 = <&pinctrl_pwm1>;
	status = "okay";
};

&ssi1 {
	fsl,mode = "i2s-slave";
	status = "okay";
};

&ssi2 {
	fsl,mode = "i2s-slave";
	status = "okay";
};

//ttymxc0
&uart1 {
	pinctrl-names = "default";
	pinctrl-0 = <&pinctrl_uart1>;
	status = "okay";
};

&uart2 {
    status = "okay";
    pinctrl-names = "default";
    pinctrl-0 = <&pinctrl_uart2>;
};

&uart3 {
    status = "okay";
	fsl,uart-has-rtscts;
	linux,rs485-enabled-at-boot-time;
	
    pinctrl-names = "default";
    pinctrl-0 = <&pinctrl_uart3>;
};

&uart4 {
    status = "okay";
    pinctrl-names = "default";
    pinctrl-0 = <&pinctrl_uart4>;
};

&uart5 {
    status = "okay";
    pinctrl-names = "default";
	//fsl,uart-has-rtscts;
    pinctrl-0 = <&pinctrl_uart5_1>;
};

&flexcan1 {
	pinctrl-names = "default";
	pinctrl-0 = <&pinctrl_can1>;
	status = "okay";
};

&usbh1 {
	vbus-supply = <&reg_usb_h1_vbus>;
	status = "okay";
};

&usbotg {
	vbus-supply = <&reg_usb_otg_vbus>;
	pinctrl-names = "default";
	pinctrl-0 = <&pinctrl_usbotg>;
	disable-over-current;
	srp-disable;
	hnp-disable;
	adp-disable;
	status = "okay";
};

&usdhc1 {
	pinctrl-names = "default";
	pinctrl-0 = <&pinctrl_usdhc1>;
	bus-width = <4>;
	//cd-gpios = <&gpio1 4 0>;
	no-1-8-v;
	keep-power-in-suspend;
	//enable-sdio-wakeup;
	status = "okay";
};

//&usdhc2 {
//	pinctrl-names = "default";
//	pinctrl-0 = <&pinctrl_usdhc2>;
//	bus-width = <8>;
//	cd-gpios = <&gpio2 2 0>;
//	wp-gpios = <&gpio2 3 0>;
//	no-1-8-v;
//	keep-power-in-suspend;
//	enable-sdio-wakeup;
//	status = "okay";
//};

//emmc
&usdhc3 {
	pinctrl-names = "default";
	pinctrl-0 = <&pinctrl_usdhc3>;
	non-removable;
	bus-width = <8>;
	//cd-gpios = <&gpio2 0 0>;
	//wp-gpios = <&gpio2 1 0>;
	no-1-8-v;
	keep-power-in-suspend;
	enable-sdio-wakeup;
	status = "okay";
};

//sd
&usdhc4 {
	pinctrl-names = "default";
	pinctrl-0 = <&pinctrl_usdhc4>;
	bus-width = <4>;
	cd-gpios = <&gpio1 04 0>;
	non-removable;
	no-1-8-v;
	keep-power-in-suspend;
	status = "okay";
};

&wdog1 {
	status = "disabled";
};

&wdog2 {
	status = "okay";
};
